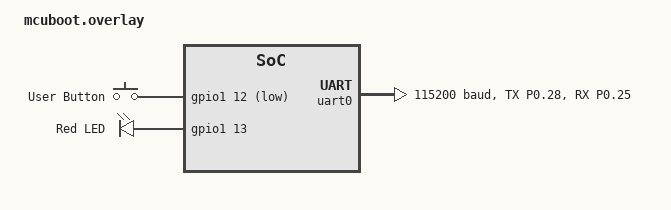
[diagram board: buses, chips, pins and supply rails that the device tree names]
/ {
    buttons {
        compatible = "gpio-keys";
        button0: button_0 {
            label = "User Button";
            gpios = <&gpio1 12 (GPIO_PULL_UP | GPIO_ACTIVE_LOW)>;
        };
    };
    leds {
        compatible = "gpio-leds";
		led0: led_0 {
			gpios = <&gpio1 13 GPIO_ACTIVE_HIGH>;
			label = "Red LED";
		};
    };
    aliases {
        mcuboot-button0 = &button0;
        mcuboot-led0 = &led0;
    };
};

&pinctrl {
	uart0_default: uart0_default {
		group1 {
			psels = <NRF_PSEL(UART_TX, 0, 28)>, <NRF_PSEL(UART_RX, 0, 25)>;
		};
	};
    uart0_sleep: uart0_sleep {
		group1 {
			psels = <NRF_PSEL(UART_TX, 0, 28)>, <NRF_PSEL(UART_RX, 0, 25)>;
			low-power-enable;
		};
	};
};

&uart0 {
    status = "okay";
    current-speed = <115200>;
    pinctrl-0 = <&uart0_default>;
    pinctrl-1 = <&uart0_sleep>;
    pinctrl-names = "default", "sleep";
};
